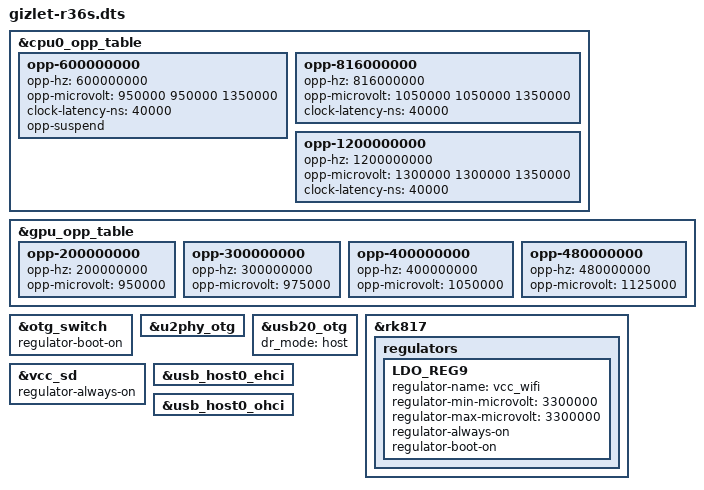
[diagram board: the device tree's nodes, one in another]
// SPDX-License-Identifier: (GPL-2.0+ OR MIT)
/*
 * Gizlet OS on the Game Console R36S. ROCKNIX's device tree describes the
 * board with the original ST7703 panel; other panels are device tree
 * overlays applied by boot.scr (see r36s-v30-panel4.dtso).
 */
#include "rk3326-gameconsole-r36s.dts"

/*
 * ROCKNIX runs the performance governor and drops the low CPU and GPU steps,
 * which leaves an idle R36S at 1.008 GHz on 1.175 V and the GPU at 560 MHz on
 * 1.15 V. Gizlet OS scales with schedutil and devfreq, so it restores the steps
 * of px30.dtsi: an idle launcher runs at 600 MHz on 0.95 V.
 */
&cpu0_opp_table {
	opp-600000000 {
		opp-hz = /bits/ 64 <600000000>;
		opp-microvolt = <950000 950000 1350000>;
		clock-latency-ns = <40000>;
		opp-suspend;
	};

	opp-816000000 {
		opp-hz = /bits/ 64 <816000000>;
		opp-microvolt = <1050000 1050000 1350000>;
		clock-latency-ns = <40000>;
	};

	opp-1200000000 {
		opp-hz = /bits/ 64 <1200000000>;
		opp-microvolt = <1300000 1300000 1350000>;
		clock-latency-ns = <40000>;
	};
};

&gpu_opp_table {
	opp-200000000 {
		opp-hz = /bits/ 64 <200000000>;
		opp-microvolt = <950000>;
	};

	opp-300000000 {
		opp-hz = /bits/ 64 <300000000>;
		opp-microvolt = <975000>;
	};

	opp-400000000 {
		opp-hz = /bits/ 64 <400000000>;
		opp-microvolt = <1050000>;
	};

	opp-480000000 {
		opp-hz = /bits/ 64 <480000000>;
		opp-microvolt = <1125000>;
	};
};

/*
 * The OTG port is a USB host, as in the stock firmware: OTG_SWITCH supplies
 * VBUS from boot. On V30 boards the on-board RTL8188EU WiFi shares this bus.
 */
&otg_switch {
	regulator-boot-on;
};

&u2phy_otg {
	status = "okay";
};

&usb20_otg {
	dr_mode = "host";
};

/*
 * The stock V30 tree names LDO9 vcc_wifi and keeps it on at 3.3 V; ROCKNIX
 * leaves it unused. The WiFi does not enumerate without it.
 */
&rk817 {
	regulators {
		LDO_REG9 {
			regulator-name = "vcc_wifi";
			regulator-min-microvolt = <3300000>;
			regulator-max-microvolt = <3300000>;
			regulator-always-on;
			regulator-boot-on;
		};
	};
};

/*
 * Both card slots take their power from LDO6 (vcc_sd), and the card-detect
 * line of an empty TF2 slot is pulled up to it. When TF1's controller
 * suspends it would switch the rail off; the line then falls, the MMC core
 * takes that for an inserted card and holds a wakeup event for 5 s, and
 * suspend aborts with EBUSY. The rail stays on in sleep anyway
 * (regulator-on-in-suspend), so it now stays on throughout.
 */
&vcc_sd {
	regulator-always-on;
};

/*
 * The host-port PHY is already enabled upstream. Its EHCI/OHCI controllers
 * expose USB devices wired to that port.
 */
&usb_host0_ehci {
	status = "okay";
};

&usb_host0_ohci {
	status = "okay";
};
